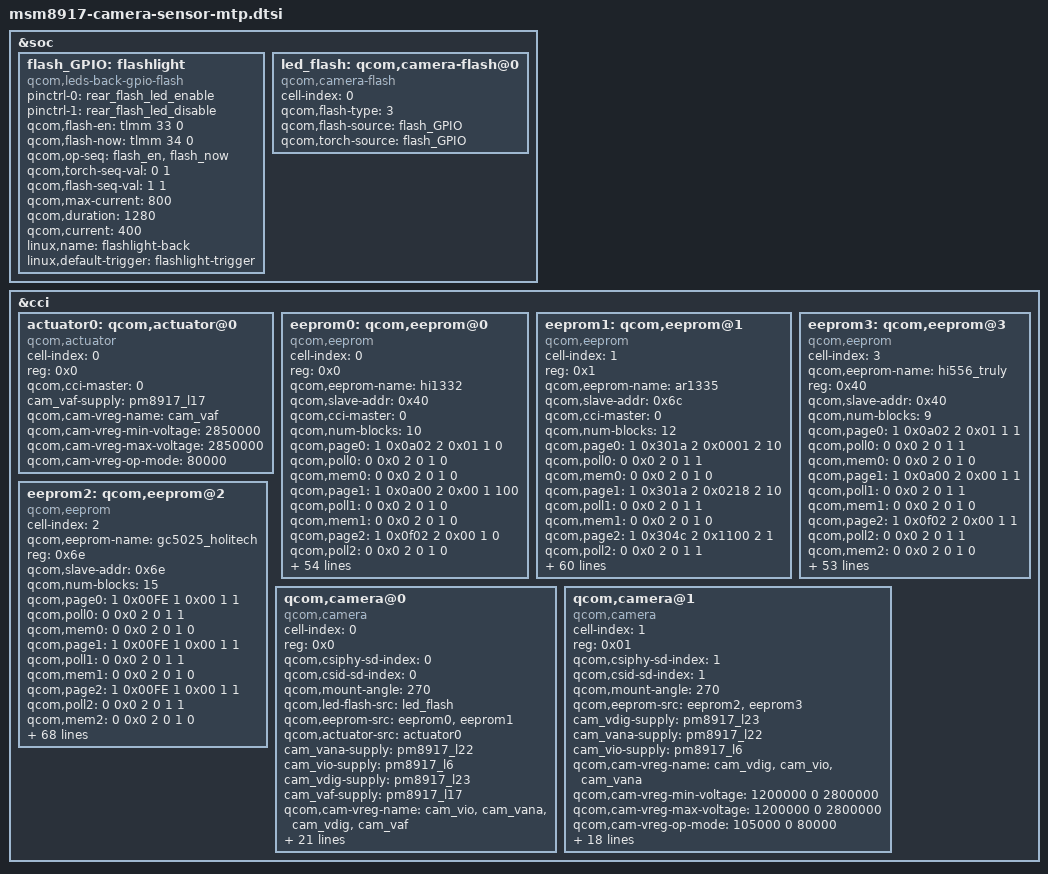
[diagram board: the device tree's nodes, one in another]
/*
 * Copyright (c) 2015-2016, The Linux Foundation. All rights reserved.
 *
 * This program is free software; you can redistribute it and/or modify
 * it under the terms of the GNU General Public License version 2 and
 * only version 2 as published by the Free Software Foundation.
 *
 * This program is distributed in the hope that it will be useful,
 * but WITHOUT ANY WARRANTY; without even the implied warranty of
 * MERCHANTABILITY or FITNESS FOR A PARTICULAR PURPOSE.  See the
 * GNU General Public License for more details.
 */

&soc {
	flash_GPIO:flashlight {
		compatible = "qcom,leds-back-gpio-flash";
		status = "okay";
		pinctrl-names = "flash_default", "flash_sleep";
		pinctrl-0 = <&rear_flash_led_enable>;
		pinctrl-1 = <&rear_flash_led_disable>;
		qcom,flash-en = <&tlmm 33 0>;
		qcom,flash-now = <&tlmm 34 0>;
		qcom,op-seq = "flash_en", "flash_now";
		qcom,torch-seq-val = <0 1>;
		qcom,flash-seq-val = <1 1>;
		qcom,max-current = <800>;
		qcom,duration = <1280>;
		qcom,current = <400>;
		linux,name = "flashlight-back";
		linux,default-trigger = "flashlight-trigger";
	};

	led_flash: qcom,camera-flash@0 {
		cell-index = <0>;
		compatible = "qcom,camera-flash";
		qcom,flash-type = <3>;
		qcom,flash-source = <&flash_GPIO>;
		qcom,torch-source = <&flash_GPIO>;
	};
};

&cci {
	actuator0: qcom,actuator@0 {
		cell-index = <0>;
		reg = <0x0>;
		compatible = "qcom,actuator";
		qcom,cci-master = <0>;
		cam_vaf-supply = <&pm8917_l17>;
		qcom,cam-vreg-name = "cam_vaf";
		qcom,cam-vreg-min-voltage = <2850000>;
		qcom,cam-vreg-max-voltage = <2850000>;
		qcom,cam-vreg-op-mode = <80000>;
	};

	eeprom0: qcom,eeprom@0 {
		cell-index = <0>;
		reg = <0x0>;
                compatible = "qcom,eeprom";
		qcom,eeprom-name = "hi1332";
		qcom,slave-addr = <0x40>;
		qcom,cci-master = <0>;
		qcom,num-blocks = <10>;
		qcom,page0 = <1 0x0a02 2 0x01 1 0>;
		qcom,poll0 = <0 0x0 2 0 1 0>;
		qcom,mem0 = <0 0x0 2 0 1 0>;
		qcom,page1 = <1 0x0a00 2 0x00 1 100>;
		qcom,poll1 = <0 0x0 2 0 1 0>;
		qcom,mem1 = <0 0x0 2 0 1 0>;
		qcom,page2 = <1 0x0f02 2 0x00 1 0>;
		qcom,poll2 = <0 0x0 2 0 1 0>;
		qcom,mem2 = <0 0x0 2 0 1 0>;
		qcom,page3 = <1 0x071a 2 0x01 1 0>;
		qcom,poll3 = <0 0x0 2 0 1 0>;
		qcom,mem3 = <0 0x0 2 0 1 0>;
		qcom,page4 = <1 0x071b 2 0x09 1 0>;
		qcom,poll4 = <0 0x0 2 0 1 0>;
		qcom,mem4 = <0 0x0 2 0 1 0>;
		qcom,page5 = <1 0x0d04 2 0x01 1 0>;
		qcom,poll5 = <0 0x0 2 0 1 0>;
		qcom,mem5 = <0 0x0 2 0 1 0>;
		qcom,page6 = <1 0x0d00 2 0x07 1 0>;
		qcom,poll6 = <0 0x0 2 0 1 0>;
		qcom,mem6 = <0 0x0 2 0 1 0>;
		qcom,page7 = <1 0x003e 2 0x10 1 0>;
		qcom,poll7 = <0 0x0 2 0 1 0>;
		qcom,mem7 = < 0 0x0 2 0 1 0>;
		qcom,page8 = <1 0x0a00 2 0x01 1 0>;
		qcom,poll8 = <0 0x0 2 0 1 0>;
		qcom,mem8 = < 0 0x0 2 0 1 0>;
		qcom,page9 = <0 0x0702 2 0x01 1 0>;
		qcom,poll9 = <0 0x0 2 0 1 0>;
		qcom,mem9 = < 2840 0x0708 2 0 1 0>;
                cam_vio-supply = <&pm8917_l6>;
                cam_vana-supply = <&pm8917_l22>;
                cam_vdig-supply = <&pm8917_l23>;
                cam_vaf-supply = <&pm8917_l17>;
                qcom,cam-vreg-name = "cam_vio", "cam_vana", "cam_vdig","cam_vaf";
                qcom,cam-vreg-min-voltage = <0 2800000 1200000 2850000>;
                qcom,cam-vreg-max-voltage = <0 2800000 1200000 2850000>;
                qcom,cam-vreg-op-mode = <0 80000 200000 100000>;
                pinctrl-names = "cam_default", "cam_suspend";
                pinctrl-0 = <&cam_sensor_mclk0_default
                                &cam_sensor_rear_default>;
                pinctrl-1 = <&cam_sensor_mclk0_sleep &cam_sensor_rear_sleep>;
                gpios = <&tlmm 26 0>,
                        <&tlmm 36 0>;
                qcom,gpio-standby = <1>;
                qcom,gpio-req-tbl-num = <0 1>;
                qcom,gpio-req-tbl-flags = <0 0>;
                qcom,gpio-req-tbl-label = "CAMIF_MCLK0",
                        "CAM_STANDBY0";

		status = "ok";

                qcom,cam-power-seq-type = "sensor_vreg","sensor_vreg","sensor_vreg","sensor_vreg",
                "sensor_clk","sensor_gpio";
                qcom,cam-power-seq-val = "cam_vio","cam_vana","cam_vdig","cam_vaf",
                                "sensor_cam_mclk","sensor_gpio_standby";
                qcom,cam-power-seq-cfg-val = <1 1 1 1 24000000 1>;
                qcom,cam-power-seq-delay =   <0 0 0 0 1 1>;

		clocks = <&clock_gcc clk_mclk0_clk_src>,
				<&clock_gcc clk_gcc_camss_mclk0_clk>;
		clock-names = "cam_src_clk", "cam_clk";
                qcom,clock-rates = <24000000 0>;
	};

	eeprom1: qcom,eeprom@1 {
		cell-index = <1>;
                reg = <0x1>;
                compatible = "qcom,eeprom";
		qcom,eeprom-name = "ar1335";
		qcom,slave-addr = <0x6c>;
		qcom,cci-master = <0>;

                qcom,num-blocks = <12>;

                qcom,page0 = <1 0x301a 2 0x0001 2 10>;
                qcom,poll0 = <0 0x0 2 0 1 1>;
                qcom,mem0 = <0 0x0 2 0 1 0>;
                qcom,page1 = <1 0x301a 2 0x0218 2 10>;
                qcom,poll1 = <0 0x0 2 0 1 1>;
                qcom,mem1 = <0 0x0 2 0 1 0>;

                qcom,page2 = <1 0x304c 2 0x1100 2 1>;
                qcom,poll2 = <0 0x0 2 0 1 1>;
                qcom,mem2 = <0 0x0 2 0 1 0>;
                qcom,page3 = <1 0x304a 2 0x0210 2 20>;
                qcom,poll3 = <0 0x0 2 0 2 1>;
                qcom,mem3 = <234 0x3800 2 0 1 0>;

                qcom,page4 = <1 0x304c 2 0x3000 2 1>;
                qcom,poll4 = <0 0x0 2 0 1 1>;
                qcom,mem4 = <0 0x0 2 0 1 0>;
                qcom,page5 = <1 0x304a 2 0x0210 2 20>;
                qcom,poll5 = <0 0x0 2 0 2 1>;
                qcom,mem5 = <22 0x3800 2 0 1 0>;

                qcom,page6 = <1 0x304c 2 0x3100 2 1>;
                qcom,poll6 = <0 0x0 2 0 1 1>;
                qcom,mem6 = <0 0x0 2 0 1 0>;
                qcom,page7 = <1 0x304a 2 0x0210 2 20>;
                qcom,poll7 = <0 0x0 2 0 2 1>;
                qcom,mem7 = <8 0x3800 2 0 1 0>;

                qcom,page8 = <1 0x304c 2 0x3700 2 1>;
                qcom,poll8 = <0 0x0 2 0 1 1>;
                qcom,mem8 = <0 0x0 2 0 1 0>;
                qcom,page9 = <1 0x304a 2 0x0210 2 20>;
                qcom,poll9 = <0 0x0 2 0 2 1>;
                qcom,mem9 = <10 0x3800 2 0 1 0>;

                qcom,page10 = <1 0x304c 2 0x3900 2 1>;
                qcom,poll10 = <0 0x0 2 0 1 1>;
                qcom,mem10 = <0 0x0 2 0 1 0>;
                qcom,page11 = <1 0x304a 2 0x0210 2 20>;
                qcom,poll11 = <0 0x0 2 0 2 1>;
                qcom,mem11 = <10 0x3800 2 0 1 0>;

                cam_vio-supply = <&pm8917_l6>;
                cam_vana-supply = <&pm8917_l22>;
                cam_vdig-supply = <&pm8917_l23>;
                cam_vaf-supply = <&pm8917_l17>;
                qcom,cam-vreg-name = "cam_vio", "cam_vana", "cam_vdig","cam_vaf";
                qcom,cam-vreg-min-voltage = <0 2800000 1200000 2850000>;
                qcom,cam-vreg-max-voltage = <0 2800000 1200000 2850000>;
                qcom,cam-vreg-op-mode = <0 80000 200000 100000>;
                pinctrl-names = "cam_default", "cam_suspend";
                pinctrl-0 = <&cam_sensor_mclk0_default
                                &cam_sensor_rear_default>;
                pinctrl-1 = <&cam_sensor_mclk0_sleep &cam_sensor_rear_sleep>;
                gpios = <&tlmm 26 0>,
                        <&tlmm 36 0>;
                qcom,gpio-standby = <1>;
                qcom,gpio-req-tbl-num = <0 1>;
                qcom,gpio-req-tbl-flags = <0 0>;
                qcom,gpio-req-tbl-label = "CAMIF_MCLK0",
                        "CAM_STANDBY0";

		status = "ok";

                qcom,cam-power-seq-type = "sensor_vreg","sensor_vreg","sensor_vreg","sensor_vreg",
                "sensor_clk","sensor_gpio";
                qcom,cam-power-seq-val = "cam_vio","cam_vana","cam_vdig","cam_vaf",
                                "sensor_cam_mclk","sensor_gpio_standby";
                qcom,cam-power-seq-cfg-val = <1 1 1 1 24000000 1>;
                qcom,cam-power-seq-delay =   <0 0 0 0 1 1>;

		clocks = <&clock_gcc clk_mclk0_clk_src>,
				<&clock_gcc clk_gcc_camss_mclk0_clk>;
		clock-names = "cam_src_clk", "cam_clk";
                qcom,clock-rates = <24000000 0>;
	};
      eeprom3: qcom,eeprom@3 {
		cell-index = <3>;
		compatible = "qcom,eeprom";
		qcom,eeprom-name = "hi556_truly";
		reg = <0x40>;
		qcom,slave-addr = <0x40>;
		qcom,num-blocks = <9>;

		qcom,page0 = <1 0x0a02 2 0x01 1 1>;
		qcom,poll0 = <0 0x0 2 0 1 1>;
		qcom,mem0 = <0 0x0 2 0 1 0>;

		qcom,page1 = <1 0x0a00 2 0x00 1 1>;
		qcom,poll1 = <0 0x0 2 0 1 1>;
		qcom,mem1 = <0 0x0 2 0 1 0>;

		qcom,page2 = <1 0x0f02 2 0x00 1 1>;
		qcom,poll2 = <0 0x0 2 0 1 1>;
		qcom,mem2 = <0 0x0 2 0 1 0>; 

		qcom,page3 = <1 0x011a 2 0x01 1 1>;
		qcom,poll3 = <0 0x0 2 0 1 1>;
		qcom,mem3 = <0 0x0 2 0 1 0>;

		qcom,page4 = <1 0x011b 2 0x09 1 1>;
		qcom,poll4 = <0 0x0 2 0 1 1>;
		qcom,mem4 = <0 0x0 2 0 1 0>;

		qcom,page5 = <1 0x0d04 2 0x01 1 1>;
		qcom,poll5 = <0 0x00 2 0 1 1>;
		qcom,mem5 = <0 0x0 2 0 1 0>;

		qcom,page6 = <1 0x0d00 2 0x07 1 1>;
		qcom,poll6 = <0 0x0 2 0 1 1>;
		qcom,mem6 = <0 0x0 2 0 1 0>;

		qcom,page7 = <1 0x003e 2 0x00 1 1>;
		qcom,poll7 = <0 0x0 2 0 1 1>;
		qcom,mem7 = <0 0x0 2 0 1 0>;

		qcom,page8 = <1 0x0a00 2 0x01 1 1>;
		qcom,poll8 = <0 0x00 2 0 1 1>;
		qcom,mem8 = <0 0x00 2 0 1 0>; 

		qcom,cci-master = <1>;
		cam_vdig-supply = <&pm8917_l23>;
		cam_vana-supply = <&pm8917_l22>;
		cam_vio-supply = <&pm8917_l6>;
		qcom,cam-vreg-name = "cam_vdig", "cam_vio", "cam_vana";
		qcom,cam-vreg-min-voltage = <1200000 0 2800000 >;
		qcom,cam-vreg-max-voltage = <1200000 0 2800000 >;
		qcom,cam-vreg-op-mode = <105000 0 80000 >;
		qcom,gpio-no-mux = <0>;
		pinctrl-names = "cam_default", "cam_suspend";
		pinctrl-0 = <&cam_sensor_mclk2_default
		&cam_sensor_front1_default>;
		pinctrl-1 = <&cam_sensor_mclk2_sleep
		&cam_sensor_front1_sleep>;
		gpios = <&tlmm 28 0>,
			<&tlmm 40 0>,
			<&tlmm 39 0>;
		qcom,gpio-reset = <1>;
		qcom,gpio-standby = <2>;
		qcom,gpio-req-tbl-num = <0 1 2>;
		qcom,gpio-req-tbl-flags = <1 0 0>;
		qcom,gpio-req-tbl-label = "CAMIF_MCLK2",
					"CAM_RESET2",
					"CAM_STANDBY2";
		status = "ok";
		qcom,cam-power-seq-type = "sensor_gpio","sensor_gpio","sensor_vreg",
		"sensor_vreg","sensor_vreg","sensor_clk","sensor_gpio","sensor_gpio";
		qcom,cam-power-seq-val = "sensor_gpio_standby","sensor_gpio_reset","cam_vio",
		"cam_vdig","cam_vana","sensor_cam_mclk","sensor_gpio_standby",
		"sensor_gpio_reset";
		qcom,cam-power-seq-cfg-val = <0 0 1 1 1 24000000 1 1>;
                 qcom,cam-power-seq-delay = <1 1 0 0 0 10 1 5>;

		 clocks = <&clock_gcc clk_mclk2_clk_src>,
	            <&clock_gcc clk_gcc_camss_mclk2_clk>;
	        clock-names = "cam_src_clk", "cam_clk";
	          qcom,clock-rates = <19200000 0>;
	};
	 eeprom2: qcom,eeprom@2 {
		cell-index = <2>;
		compatible = "qcom,eeprom";
		qcom,eeprom-name = "gc5025_holitech";
		reg = <0x6e>;
		qcom,slave-addr = <0x6e>;
		qcom,num-blocks = <15>;

		qcom,page0 = <1 0x00FE 1 0x00 1 1>;
		qcom,poll0 = <0 0x0 2 0 1 1>;
		qcom,mem0 = <0 0x0 2 0 1 0>;

		qcom,page1 = <1 0x00FE 1 0x00 1 1>;
		qcom,poll1 = <0 0x0 2 0 1 1>;
		qcom,mem1 = <0 0x0 2 0 1 0>;

		qcom,page2 = <1 0x00FE 1 0x00 1 1>;
		qcom,poll2 = <0 0x0 2 0 1 1>;
		qcom,mem2 = <0 0x0 2 0 1 0>; 

		qcom,page3 = <1 0x00F7 1 0x01 1 1>;
		qcom,poll3 = <0 0x0 2 0 1 1>;
		qcom,mem3 = <0 0x0 2 0 1 0>;

		qcom,page4 = <1 0x00F8 1 0x11 1 1>;
		qcom,poll4 = <0 0x0 2 0 1 1>;
		qcom,mem4 = <0 0x0 2 0 1 0>;

		qcom,page5 = <1 0x00F9 1 0x00 1 1>;
		qcom,poll5 = <0 0x00 2 0 1 1>;
		qcom,mem5 = <0 0x0 2 0 1 0>;

		qcom,page6 = <1 0x00FA 1 0xa0 1 1>;
		qcom,poll6 = <0 0x0 2 0 1 1>;
		qcom,mem6 = <0 0x0 2 0 1 0>;

		qcom,page7 = <1 0x00FC 1 0x2e 1 1>;
		qcom,poll7 = <0 0x0 2 0 1 1>;
		qcom,mem7 = <0 0x0 2 0 1 0>;

		qcom,page8 = <1 0x00FA 1 0xb0 1 1>;
		qcom,poll8 = <0 0x00 2 0 1 1>;
		qcom,mem8 = <0 0x00 2 0 1 0>; 

		qcom,page9 = <1 0x00d4 1 0x84 1 1>;
		qcom,poll9 = <0 0x0 2 0 1 1>;
		qcom,mem9 = <0 0x0 2 0 1 0>;

		qcom,page10 = <1 0x00d5 1 0x00 1 1>;
		qcom,poll10 = <0 0x0 2 0 1 1>;
		qcom,mem10 = <0 0x0 2 0 1 0>;

		qcom,page11 = <1 0x00f3 1 0x20 1 1>;
		qcom,poll11 = <0 0x00 2 0 1 1>;
		qcom,mem11 = <0 0x0 2 0 1 0>; 

		qcom,page12 = <1 0x00f3 1 0x88 1 1>;
		qcom,poll12 = <0 0x0 2 0 1 1>;
		qcom,mem12 = <37 0xd7 1 0 1 0>;

		qcom,page13 = <1 0x00fa 1 0xa0 1 1>;
		qcom,poll13 = <0 0x00 2 0 1 1>;
		qcom,mem13= <0 0x0 2 0 1 0>; 

		qcom,page14 = <1 0x00d4 1 0x00 1 1>;
		qcom,poll14 = <0 0x00 2 0 1 1>;
		qcom,mem14 = <0 0x0 2 0 1 0>; 

		qcom,cci-master = <1>;
		cam_vdig-supply = <&pm8917_l23>;
		cam_vana-supply = <&pm8917_l22>;
		cam_vio-supply = <&pm8917_l6>;
		qcom,cam-vreg-name = "cam_vdig", "cam_vio", "cam_vana";
		qcom,cam-vreg-min-voltage = <1200000 0 2800000 >;
		qcom,cam-vreg-max-voltage = <1200000 0 2800000 >;
		qcom,cam-vreg-op-mode = <105000 0 80000 >;
		qcom,gpio-no-mux = <0>;
		pinctrl-names = "cam_default", "cam_suspend";
		pinctrl-0 = <&cam_sensor_mclk2_default
		&cam_sensor_front1_default>;
		pinctrl-1 = <&cam_sensor_mclk2_sleep
		&cam_sensor_front1_sleep>;
		gpios = <&tlmm 28 0>,
			<&tlmm 40 0>,
			<&tlmm 39 0>;
		qcom,gpio-reset = <1>;
		qcom,gpio-standby = <2>;
		qcom,gpio-req-tbl-num = <0 1 2>;
		qcom,gpio-req-tbl-flags = <1 0 0>;
		qcom,gpio-req-tbl-label = "CAMIF_MCLK2",
					"CAM_RESET2",
					"CAM_STANDBY2";
		status = "ok";
		qcom,cam-power-seq-type = "sensor_vreg","sensor_vreg","sensor_vreg",
		"sensor_clk","sensor_gpio","sensor_gpio";
		qcom,cam-power-seq-val = "cam_vio","cam_vdig","cam_vana",
		"sensor_cam_mclk","sensor_gpio_standby","sensor_gpio_reset";
		qcom,cam-power-seq-cfg-val = <1 1 1 24000000 1 1>;
                 qcom,cam-power-seq-delay = <10 10 10 5 1 1>;

		 clocks = <&clock_gcc clk_mclk2_clk_src>,
	            <&clock_gcc clk_gcc_camss_mclk2_clk>;
	        clock-names = "cam_src_clk", "cam_clk";
	          qcom,clock-rates = <19200000 0>;
	};
	qcom,camera@0 {
		cell-index = <0>;
		compatible = "qcom,camera";
		reg = <0x0>;
		qcom,csiphy-sd-index = <0>;
		qcom,csid-sd-index = <0>;
		qcom,mount-angle = <270>;
		qcom,led-flash-src = <&led_flash>;
		qcom,eeprom-src = <&eeprom0 &eeprom1>;
		qcom,actuator-src = <&actuator0>;
		cam_vana-supply = <&pm8917_l22>;
		cam_vio-supply = <&pm8917_l6>;
		cam_vdig-supply = <&pm8917_l23>;
		cam_vaf-supply = <&pm8917_l17>;
		qcom,cam-vreg-name = "cam_vio", "cam_vana", "cam_vdig","cam_vaf";
		qcom,cam-vreg-min-voltage = <0 2800000 1200000 2850000>;
		qcom,cam-vreg-max-voltage = <0 2800000 1200000 2850000>;
		qcom,cam-vreg-op-mode = <0 80000 200000 100000>;
		pinctrl-names = "cam_default", "cam_suspend";
		pinctrl-0 = <&cam_sensor_mclk0_default
				&cam_sensor_rear_default>;
		pinctrl-1 = <&cam_sensor_mclk0_sleep &cam_sensor_rear_sleep>;
		gpios = <&tlmm 26 0>,
			<&tlmm 36 0>;
		qcom,gpio-standby = <1>;
		qcom,gpio-req-tbl-num = <0 1>;
		qcom,gpio-req-tbl-flags = <0 0>;
		qcom,gpio-req-tbl-label = "CAMIF_MCLK0",
			"CAM_STANDBY0";
		qcom,sensor-position = <0>;
		qcom,sensor-mode = <0>;
		qcom,cci-master = <0>;
		status = "ok";
		clocks = <&clock_gcc clk_mclk0_clk_src>,
				<&clock_gcc clk_gcc_camss_mclk0_clk>;
		clock-names = "cam_src_clk", "cam_clk";
		qcom,clock-rates = <24000000 0>;
	};

   qcom,camera@1 {
       cell-index = <1>;
       compatible = "qcom,camera";
       reg = <0x01>;
       qcom,csiphy-sd-index = <1>;
       qcom,csid-sd-index = <1>;
       qcom,mount-angle = <270>;
       qcom,eeprom-src = <&eeprom2 &eeprom3>;
       cam_vdig-supply = <&pm8917_l23>;
       cam_vana-supply = <&pm8917_l22>;
       cam_vio-supply = <&pm8917_l6>;
       qcom,cam-vreg-name = "cam_vdig", "cam_vio", "cam_vana";
       qcom,cam-vreg-min-voltage = <1200000 0 2800000 >;
       qcom,cam-vreg-max-voltage = <1200000 0 2800000 >;
       qcom,cam-vreg-op-mode = <105000 0 80000 >;
       qcom,gpio-no-mux = <0>;
       pinctrl-names = "cam_default", "cam_suspend";
       pinctrl-0 = <&cam_sensor_mclk2_default
           &cam_sensor_front1_default>;
       pinctrl-1 = <&cam_sensor_mclk2_sleep
           &cam_sensor_front1_sleep>;
       gpios = <&tlmm 28 0>,
           <&tlmm 40 0>,
           <&tlmm 39 0>;
       qcom,gpio-reset = <1>;
       qcom,gpio-standby = <2>;
       qcom,gpio-req-tbl-num = <0 1 2>;
       qcom,gpio-req-tbl-flags = <1 0 0>;
       qcom,gpio-req-tbl-label = "CAMIF_MCLK2",
              "CAM_RESET2",
              "CAM_STANDBY2";
       qcom,sensor-position = <1>;
       qcom,sensor-mode = <0>;
       qcom,cci-master = <1>;
       status = "ok";
       clocks = <&clock_gcc clk_mclk2_clk_src>,
          <&clock_gcc clk_gcc_camss_mclk2_clk>;
       clock-names = "cam_src_clk", "cam_clk";
       qcom,clock-rates = <24000000 0>;
     };
   };
